# STM32H7P5 register map
File version: 2.0.0
CPU: CM7 r1p2, little endian, MPU, FPU, 4 interrupt priority bits
Registers are 32-bit, read-write, reset 0x0 unless marked. A register's access mark holds for its fields unless they carry their own. Offsets are from the block's base; [hi:lo] are bit positions; {n}, {i} and the like mark numbered series; 'fields as' and 'values as' point back to an identical list.

## DTS — DTS register block
Base 0x58006800
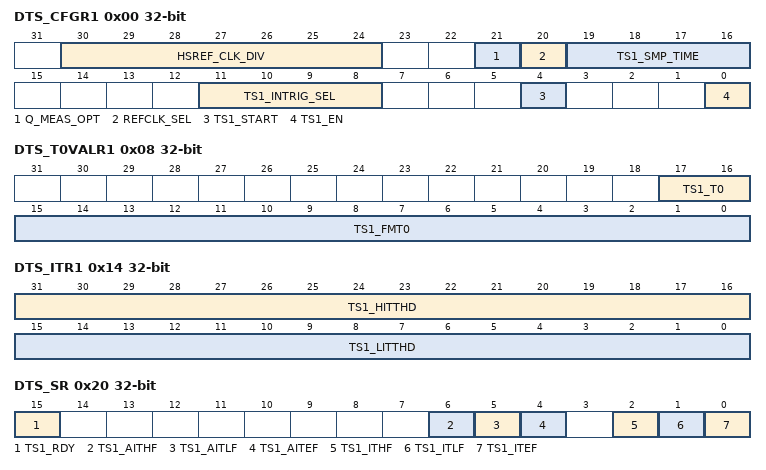
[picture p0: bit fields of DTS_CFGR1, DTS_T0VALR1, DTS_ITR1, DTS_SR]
0x00 DTS_CFGR1 — Temperature sensor configuration register 1
  [30:24] HSREF_CLK_DIV — High speed clock division ratio
    0=No divider; 1=No divider; 2=1/2 division ratio; 127=1/127 division ratio
  [21] Q_MEAS_OPT — Quick measurement option bit
    0=Measurement with calibration; 1=Measurement without calibration
  [20] REFCLK_SEL — Reference clock selection bit
    0=High speed reference clock (PCLK); 1=Low speed reference clock (LSE)
  [19:16] TS1_SMP_TIME — Sampling time for temperature sensor 1
  [11:8] TS1_INTRIG_SEL — Input trigger selection bit for temperature sensor 1
  [4] TS1_START — Start frequency measurement on temperature sensor 1
    0=No software trigger; 1=Software trigger for a frequency measurement. (only if TS1 is ready).
  [0] TS1_EN — Temperature sensor 1 enable bit
    0=Temperature sensor 1 disabled; 1=Temperature sensor 1 enabled
0x08 DTS_T0VALR1 ro (reset mask 0xFFF00000) — Temperature sensor T0 value register 1
  [17:16] TS1_T0 — Engineering value of the T0 temperature for temperature sensor 1.
    0=30 degree C; 1=140 degree C
  [15:0] TS1_FMT0 — Engineering value of the frequency measured at T0 for
0x10 DTS_RAMPVALR ro reset not defined — Temperature sensor ramp value register
  [15:0] TS1_RAMP_COEFF — Engineering value of the ramp coefficient for the temperature sensor 1.
0x14 DTS_ITR1 — Temperature sensor interrupt threshold register 1
  [31:16] TS1_HITTHD — High interrupt threshold for temperature sensor 1
  [15:0] TS1_LITTHD — Low interrupt threshold for temperature sensor 1
0x1C DTS_DR — Temperature sensor data register
  [15:0] TS1_MFREQ — Value of the counter output value for temperature sensor 1
0x20 DTS_SR ro — Temperature sensor status register
  [15] TS1_RDY — Temperature sensor 1 ready flag
    0=Temperature sensor 1 busy; 1=Temperature sensor 1 ready
  [6] TS1_AITHF — Asynchronous interrupt flag for high threshold on temperature sensor 1
    0=High threshold not reached on temperature sensor 1; 1=High threshold reached on temperature sensor 1
  [5] TS1_AITLF — Asynchronous interrupt flag for low threshold on temperature sensor 1
    0=Low threshold not reached on temperature sensor 1; 1=Low threshold reached on temperature sensor 1
  [4] TS1_AITEF — Asynchronous interrupt flag for end of measure on temperature sensor 1
    0=End of measure not detected on temperature sensor 1; 1=End of measure detected on temperature sensor 1
  [2] TS1_ITHF — Interrupt flag for high threshold on temperature sensor 1, synchronized on PCLK
    values as TS1_AITHF
  [1] TS1_ITLF — Interrupt flag for low threshold on temperature sensor 1, synchronized on PCLK.
    values as TS1_AITLF
  [0] TS1_ITEF — Interrupt flag for end of measurement on temperature sensor 1, synchronized on PCLK.
    0=No end of measurement detected on temperature sensor 1; 1=End of measure detected on temperature sensor 1
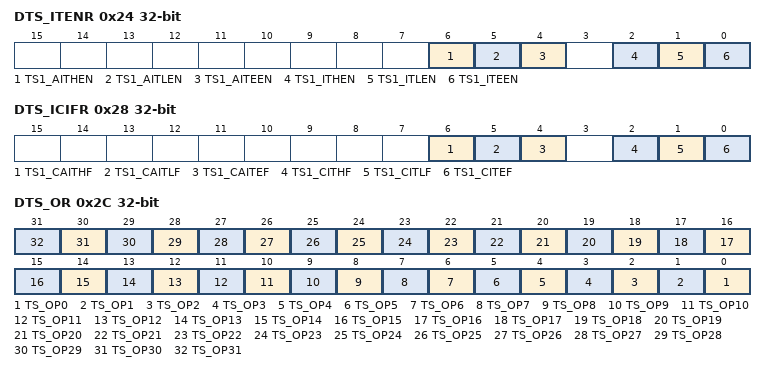
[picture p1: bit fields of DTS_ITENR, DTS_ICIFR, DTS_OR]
0x24 DTS_ITENR — Temperature sensor interrupt enable register
  [6] TS1_AITHEN — Asynchronous interrupt enable flag on high threshold for temperature sensor 1.
    0=Asynchronous interrupt on high threshold disabled for temperature sensor 1; 1=Asynchronous interrupt on high threshold enabled for temperature sensor 1
  [5] TS1_AITLEN — Asynchronous interrupt enable flag for low threshold on temperature sensor 1.
    0=Asynchronous interrupt on low threshold disabled for temperature sensor 1; 1=Asynchronous interrupt on low threshold enabled for temperature sensor 1
  [4] TS1_AITEEN — Asynchronous interrupt enable flag for end of measurement on temperature sensor 1
    0=Asynchronous interrupt for end of measurement disabled on temperature sensor 1; 1=Asynchronous interrupt for end of measurement enabled on temperature sensor 1
  [2] TS1_ITHEN — Interrupt enable flag for high threshold on temperature sensor 1, synchronized on PCLK.
    0=Synchronous interrupt for high threshold disabled on temperature sensor 1; 1=Synchronous interrupt for high threshold enabled on temperature sensor 1
  [1] TS1_ITLEN — Interrupt enable flag for low threshold on temperature sensor 1, synchronized on PCLK.
    0=Synchronous interrupt for low threshold disabled on temperature sensor 1; 1=Synchronous interrupt for low threshold enabled on temperature sensor 1
  [0] TS1_ITEEN — Interrupt enable flag for end of measurement on temperature sensor 1, synchronized on PCLK.
    0=Synchronous interrupt for end of measurement disabled on temperature sensor 1; 1=Synchronous interrupt for end of measurement enabled on temperature sensor 1
0x28 DTS_ICIFR — Temperature sensor clear interrupt flag register
  [6] TS1_CAITHF — Asynchronous interrupt clear flag for high threshold on temperature sensor 1
  [5] TS1_CAITLF — Asynchronous interrupt clear flag for low threshold on temperature sensor 1
  [4] TS1_CAITEF — Write once bit. Clear the asynchronous IT flag for End Of Measure for thermal sensor 1.
  [2] TS1_CITHF — Interrupt clear flag for high threshold on temperature sensor 1
  [1] TS1_CITLF — Interrupt clear flag for low threshold on temperature sensor 1
  [0] TS1_CITEF — Interrupt clear flag for end of measurement on temperature sensor 1
0x2C DTS_OR — Temperature sensor option register
  [n] TS_OP{n} (n=0..31) — general purpose option bits
